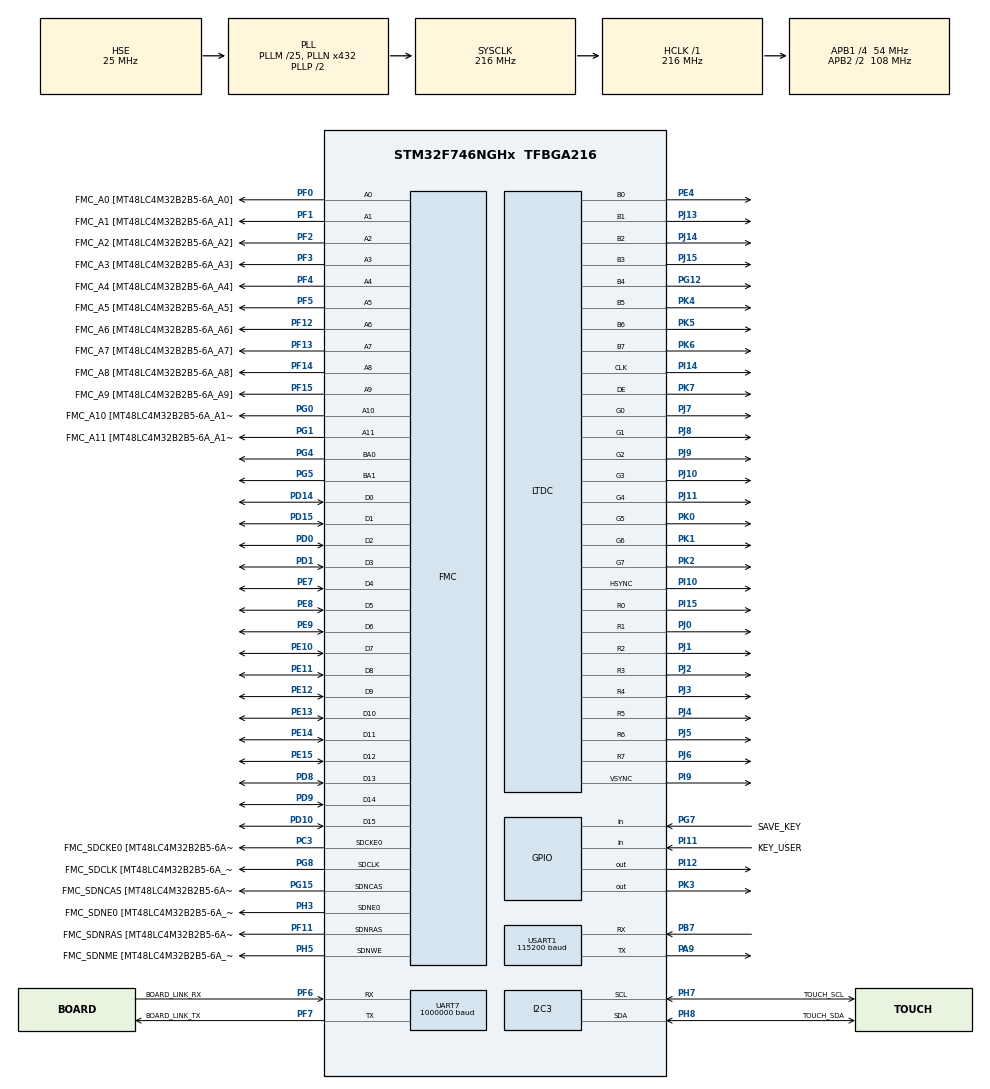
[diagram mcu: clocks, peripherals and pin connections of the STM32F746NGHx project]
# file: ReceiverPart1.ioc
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Dma.Request0=UART7_RX
Dma.UART7_RX.0.Direction=DMA_PERIPH_TO_MEMORY
Dma.UART7_RX.0.FIFOMode=DMA_FIFOMODE_DISABLE
Dma.UART7_RX.0.Instance=DMA1_Stream3
Dma.UART7_RX.0.MemDataAlignment=DMA_MDATAALIGN_BYTE
Dma.UART7_RX.0.MemInc=DMA_MINC_ENABLE
Dma.UART7_RX.0.Mode=DMA_CIRCULAR
Dma.UART7_RX.0.PeriphDataAlignment=DMA_PDATAALIGN_BYTE
Dma.UART7_RX.0.PeriphInc=DMA_PINC_DISABLE
Dma.UART7_RX.0.Priority=DMA_PRIORITY_HIGH
CORTEX_M7.default_mode_Activation=0
FMC.CASLatency1=FMC_SDRAM_CAS_LATENCY_2
FMC.ExitSelfRefreshDelay1=7
FMC.LoadToActiveDelay1=2
FMC.RCDDelay1=2
FMC.RPDelay1=2
FMC.ReadBurst1=FMC_SDRAM_RBURST_ENABLE
FMC.RowCycleDelay1=7
FMC.SDClockPeriod1=FMC_SDRAM_CLOCK_PERIOD_2
FMC.SelfRefreshTime1=4
FMC.WriteRecoveryTime1=2
I2C3.Timing=0x00C0EAFF
LTDC.ActiveH=272
LTDC.ActiveW=480
LTDC.Alpha_L0=255
LTDC.FBStartAdress_L0=0xC0000000
LTDC.HBP=13
LTDC.HFP=32
LTDC.HSync=41
LTDC.ImageHeight_L0=272
LTDC.ImageWidth_L0=480
LTDC.Layers=0
LTDC.PixelFormat_L0=LTDC_PIXEL_FORMAT_RGB565
LTDC.VBP=2
LTDC.VFP=2
LTDC.VSync=10
LTDC.WindowX1_L0=480
LTDC.WindowY1_L0=272
Mcu.Family=STM32F7
Mcu.Name=STM32F746NGHx
Mcu.Package=TFBGA216
NVIC.DMA1_Stream3_IRQn=true\:5\:0\:false\:false\:true\:true\:true\:true
NVIC.PriorityGroup=NVIC_PRIORITYGROUP_4
NVIC.USART1_IRQn=true\:5\:0\:false\:false\:true\:true\:true\:true
PA13.Mode=Serial_Wire
PA13.Signal=SYS_JTMS-SWDIO
PA14.Mode=Serial_Wire
PA14.Signal=SYS_JTCK-SWCLK
PA9.Mode=Asynchronous
PA9.Signal=USART1_TX
PB7.Mode=Asynchronous
PB7.Signal=USART1_RX
PC3.GPIO_Label=FMC_SDCKE0 [MT48LC4M32B2B5-6A_CKE]
PC3.Mode=SdramChipSelect1_1
PC3.Signal=FMC_SDCKE0
PD0.Signal=FMC_D2_DA2
PD1.Signal=FMC_D3_DA3
PD10.Signal=FMC_D15_DA15
PD14.Signal=FMC_D0_DA0
PD15.Signal=FMC_D1_DA1
PD8.Signal=FMC_D13_DA13
PD9.Signal=FMC_D14_DA14
PE0.GPIO_Label=FMC_NBL0 [MT48LC4M32B2B5-6A_DQM0]
PE0.Signal=FMC_NBL0
PE1.GPIO_Label=FMC_NBL1 [MT48LC4M32B2B5-6A_DQM1]
PE1.Signal=FMC_NBL1
PE10.Signal=FMC_D7_DA7
PE11.Signal=FMC_D8_DA8
PE12.Signal=FMC_D9_DA9
PE13.Signal=FMC_D10_DA10
PE14.Signal=FMC_D11_DA11
PE15.Signal=FMC_D12_DA12
PE7.Signal=FMC_D4_DA4
PE8.Signal=FMC_D5_DA5
PE9.Signal=FMC_D6_DA6
PF0.GPIO_Label=FMC_A0 [MT48LC4M32B2B5-6A_A0]
PF0.Signal=FMC_A0
PF1.GPIO_Label=FMC_A1 [MT48LC4M32B2B5-6A_A1]
PF1.Signal=FMC_A1
PF11.GPIO_Label=FMC_SDNRAS [MT48LC4M32B2B5-6A_RAS]
PF11.Signal=FMC_SDNRAS
PF12.GPIO_Label=FMC_A6 [MT48LC4M32B2B5-6A_A6]
PF12.Signal=FMC_A6
PF13.GPIO_Label=FMC_A7 [MT48LC4M32B2B5-6A_A7]
PF13.Signal=FMC_A7
PF14.GPIO_Label=FMC_A8 [MT48LC4M32B2B5-6A_A8]
PF14.Signal=FMC_A8
PF15.GPIO_Label=FMC_A9 [MT48LC4M32B2B5-6A_A9]
PF15.Signal=FMC_A9
PF2.GPIO_Label=FMC_A2 [MT48LC4M32B2B5-6A_A2]
PF2.Signal=FMC_A2
PF3.GPIO_Label=FMC_A3 [MT48LC4M32B2B5-6A_A3]
PF3.Signal=FMC_A3
PF4.GPIO_Label=FMC_A4 [MT48LC4M32B2B5-6A_A4]
PF4.Signal=FMC_A4
PF5.GPIO_Label=FMC_A5 [MT48LC4M32B2B5-6A_A5]
PF5.Signal=FMC_A5
PF6.GPIO_Label=BOARD_LINK_RX
PF6.Mode=Asynchronous
PF6.Signal=UART7_RX
PG0.GPIO_Label=FMC_A10 [MT48LC4M32B2B5-6A_A10]
PG0.Signal=FMC_A10
PG1.GPIO_Label=FMC_A11 [MT48LC4M32B2B5-6A_A11]
PG1.Signal=FMC_A11
PF7.GPIO_Label=BOARD_LINK_TX
PF7.Mode=Asynchronous
PF7.Signal=UART7_TX
PG15.GPIO_Label=FMC_SDNCAS [MT48LC4M32B2B5-6A_CAS]
PG15.Signal=FMC_SDNCAS
PG4.Signal=FMC_A14_BA0
PG5.Signal=FMC_A15_BA1
PG8.GPIO_Label=FMC_SDCLK [MT48LC4M32B2B5-6A_CLK]
PG8.Signal=FMC_SDCLK
PH0/OSC_IN.Mode=HSE-External-Oscillator
PH0/OSC_IN.Signal=RCC_OSC_IN
PH1/OSC_OUT.Mode=HSE-External-Oscillator
PH1/OSC_OUT.Signal=RCC_OSC_OUT
PH3.GPIO_Label=FMC_SDNE0 [MT48LC4M32B2B5-6A_CS]
PH3.Mode=SdramChipSelect1_1
PH3.Signal=FMC_SDNE0
PH5.GPIO_Label=FMC_SDNME [MT48LC4M32B2B5-6A_WE]
PH5.Signal=FMC_SDNWE
PH7.GPIO_Label=TOUCH_SCL
PH7.Mode=I2C
PH7.Signal=I2C3_SCL
PH8.GPIO_Label=TOUCH_SDA
PH8.Mode=I2C
PH8.Signal=I2C3_SDA
PI11.GPIO_Label=KEY_USER
PI11.GPIO_PuPd=GPIO_PULLUP
PI11.Signal=GPIO_Input
PG7.GPIO_Label=SAVE_KEY
PG7.GPIO_PuPd=GPIO_PULLUP
PG7.Signal=GPIO_Input
PI12.PinState=GPIO_PIN_SET
PI12.Signal=GPIO_Output
PK3.Signal=GPIO_Output
PE4.Mode=RGB565
PE4.Signal=LTDC_B0
PJ13.Mode=RGB565
PJ13.Signal=LTDC_B1
PJ14.Mode=RGB565
PJ14.Signal=LTDC_B2
PJ15.Mode=RGB565
PJ15.Signal=LTDC_B3
PG12.Mode=RGB565
PG12.Signal=LTDC_B4
PK4.Mode=RGB565
PK4.Signal=LTDC_B5
PK5.Mode=RGB565
PK5.Signal=LTDC_B6
PK6.Mode=RGB565
PK6.Signal=LTDC_B7
PJ7.Mode=RGB565
PJ7.Signal=LTDC_G0
PJ8.Mode=RGB565
PJ8.Signal=LTDC_G1
PJ9.Mode=RGB565
PJ9.Signal=LTDC_G2
PJ10.Mode=RGB565
PJ10.Signal=LTDC_G3
PJ11.Mode=RGB565
PJ11.Signal=LTDC_G4
PK0.Mode=RGB565
PK0.Signal=LTDC_G5
PK1.Mode=RGB565
PK1.Signal=LTDC_G6
PK2.Mode=RGB565
PK2.Signal=LTDC_G7
PI15.Mode=RGB565
PI15.Signal=LTDC_R0
PJ0.Mode=RGB565
PJ0.Signal=LTDC_R1
PJ1.Mode=RGB565
PJ1.Signal=LTDC_R2
PJ2.Mode=RGB565
PJ2.Signal=LTDC_R3
PJ3.Mode=RGB565
PJ3.Signal=LTDC_R4
PJ4.Mode=RGB565
PJ4.Signal=LTDC_R5
PJ5.Mode=RGB565
PJ5.Signal=LTDC_R6
PJ6.Mode=RGB565
PJ6.Signal=LTDC_R7
PI10.Mode=RGB565
PI10.Signal=LTDC_HSYNC
PI9.Mode=RGB565
PI9.Signal=LTDC_VSYNC
PI14.Mode=RGB565
PI14.Signal=LTDC_CLK
PK7.Mode=RGB565
PK7.Signal=LTDC_DE
ProjectManager.HeapSize=0x200
ProjectManager.StackSize=0x400
ProjectManager.TargetToolchain=STM32CubeIDE
RCC.AHBFreq_Value=216000000
RCC.APB1CLKDivider=RCC_HCLK_DIV4
RCC.APB1Freq_Value=54000000
RCC.APB1TimFreq_Value=108000000
RCC.APB2CLKDivider=RCC_HCLK_DIV2
RCC.APB2Freq_Value=108000000
RCC.APB2TimFreq_Value=216000000
RCC.CortexFreq_Value=216000000
RCC.HCLKFreq_Value=216000000
RCC.HSE_VALUE=25000000
RCC.HSI_VALUE=16000000
RCC.LSE_VALUE=32768
RCC.PLLM=25
RCC.PLLN=432
RCC.PLLSAIN=192
RCC.PLLSAIR=5
RCC.PLLSAIRDiv=RCC_PLLSAIDIVR_4
RCC.PLLSourceVirtual=RCC_PLLSOURCE_HSE
RCC.SYSCLKFreq_VALUE=216000000
RCC.SYSCLKSource=RCC_SYSCLKSOURCE_PLLCLK
RCC.USBFreq_Value=216000000
RCC.VCOOutputFreq_Value=432000000
SH.FMC_A0.0=FMC_A0,12b-sda1
SH.FMC_A1.0=FMC_A1,12b-sda1
SH.FMC_A10.0=FMC_A10,12b-sda1
SH.FMC_A11.0=FMC_A11,12b-sda1
SH.FMC_A14_BA0.0=FMC_BA0,FourSdramBanks1
SH.FMC_A15_BA1.0=FMC_BA1,FourSdramBanks1
SH.FMC_A2.0=FMC_A2,12b-sda1
SH.FMC_A3.0=FMC_A3,12b-sda1
SH.FMC_A4.0=FMC_A4,12b-sda1
SH.FMC_A5.0=FMC_A5,12b-sda1
SH.FMC_A6.0=FMC_A6,12b-sda1
SH.FMC_A7.0=FMC_A7,12b-sda1
SH.FMC_A8.0=FMC_A8,12b-sda1
SH.FMC_A9.0=FMC_A9,12b-sda1
SH.FMC_D0_DA0.0=FMC_D0,sd-16b-d1
SH.FMC_D10_DA10.0=FMC_D10,sd-16b-d1
SH.FMC_D11_DA11.0=FMC_D11,sd-16b-d1
SH.FMC_D12_DA12.0=FMC_D12,sd-16b-d1
SH.FMC_D13_DA13.0=FMC_D13,sd-16b-d1
SH.FMC_D14_DA14.0=FMC_D14,sd-16b-d1
SH.FMC_D15_DA15.0=FMC_D15,sd-16b-d1
SH.FMC_D1_DA1.0=FMC_D1,sd-16b-d1
SH.FMC_D2_DA2.0=FMC_D2,sd-16b-d1
SH.FMC_D3_DA3.0=FMC_D3,sd-16b-d1
SH.FMC_D4_DA4.0=FMC_D4,sd-16b-d1
SH.FMC_D5_DA5.0=FMC_D5,sd-16b-d1
SH.FMC_D6_DA6.0=FMC_D6,sd-16b-d1
SH.FMC_D7_DA7.0=FMC_D7,sd-16b-d1
SH.FMC_D8_DA8.0=FMC_D8,sd-16b-d1
SH.FMC_D9_DA9.0=FMC_D9,sd-16b-d1
SH.FMC_NBL0.0=FMC_NBL0
SH.FMC_NBL1.0=FMC_NBL1
SH.FMC_SDCLK.0=FMC_SDCLK,12b-sda1
SH.FMC_SDNCAS.0=FMC_SDNCAS,12b-sda1
SH.FMC_SDNRAS.0=FMC_SDNRAS,12b-sda1
SH.FMC_SDNWE.0=FMC_SDNWE,12b-sda1
USART1.BaudRate=115200
USART1.VirtualMode-Asynchronous=VM_ASYNC
UART7.BaudRate=1000000
UART7.VirtualMode-Asynchronous=VM_ASYNC
board=STM32F746G-DISCO

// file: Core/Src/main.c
/* USER CODE BEGIN Header */
/**
  ******************************************************************************
  * @file           : main.c
  * @brief          : Main program body
  ******************************************************************************
  * @attention
  *
  * Copyright (c) 2026 STMicroelectronics.
  * All rights reserved.
  *
  * This software is licensed under terms that can be found in the LICENSE file
  * in the root directory of this software component.
  * If no LICENSE file comes with this software, it is provided AS-IS.
  *
  ******************************************************************************
  */
/* USER CODE END Header */
#include "main.h"
#include "ltdc.h"
#include "usart.h"
#include "gpio.h"
#include "fmc.h"
#include "i2c.h"

/* USER CODE BEGIN Includes */
#include "app_acquisition.h"
#include "app_role.h"
#include "app_receiver.h"
/* USER CODE END Includes */

void SystemClock_Config(void);

int main(void)
{

  /* MCU Configuration--------------------------------------------------------*/

  /* Reset of all peripherals, Initializes the Flash interface and the Systick. */
  HAL_Init();

  /* Configure the system clock */
  SystemClock_Config();

  /* Initialize all configured peripherals */
  MX_GPIO_Init();
  MX_USART1_UART_Init();   /* ST-LINK VCP，供电脑调试 */
  MX_UART7_UART_Init();    /* PF7/PF6，两块开发板之间的 1 Mbps 链路 */

#if APP_ROLE == APP_ROLE_RECEIVER
  MX_FMC_Init();
  MX_LTDC_Init();
  MX_I2C3_Init();
#endif
  /* USER CODE BEGIN 2 */
  /*
   * 以上代码由 CubeMX 生成。
   * 这里进入我们自己的应用层：初始化 SDRAM、帧缓冲区、UART 接收和界面。
   */
#if APP_ROLE == APP_ROLE_RECEIVER
  App_ReceiverInit();
#else
  App_AcquisitionInit();
#endif
  /* USER CODE END 2 */

  /* Infinite loop */
  while (1)
  {

    /* USER CODE BEGIN 3 */
#if APP_ROLE == APP_ROLE_RECEIVER
    /* 解析板间串口/PC 调试串口，扫描触摸按键并刷新波形。 */
    App_ReceiverLoop();
#else
    /* 采集演示固件：通过 UART7 发送双通道测试帧并接收换档命令。 */
    App_AcquisitionLoop();
#endif
  }
  /* USER CODE END 3 */
}

void SystemClock_Config(void)
{
  RCC_OscInitTypeDef RCC_OscInitStruct = {0};
  RCC_ClkInitTypeDef RCC_ClkInitStruct = {0};

  /** Configure the main internal regulator output voltage
  */
  __HAL_RCC_PWR_CLK_ENABLE();
  __HAL_PWR_VOLTAGESCALING_CONFIG(PWR_REGULATOR_VOLTAGE_SCALE1);

  /** Initializes the RCC Oscillators according to the specified parameters
  * in the RCC_OscInitTypeDef structure.
  */
  RCC_OscInitStruct.OscillatorType = RCC_OSCILLATORTYPE_HSE;
  RCC_OscInitStruct.HSEState = RCC_HSE_ON;
  RCC_OscInitStruct.PLL.PLLState = RCC_PLL_ON;
  RCC_OscInitStruct.PLL.PLLSource = RCC_PLLSOURCE_HSE;
  RCC_OscInitStruct.PLL.PLLM = 25;
  RCC_OscInitStruct.PLL.PLLN = 432;
  RCC_OscInitStruct.PLL.PLLP = RCC_PLLP_DIV2;
  RCC_OscInitStruct.PLL.PLLQ = 2;
  if (HAL_RCC_OscConfig(&RCC_OscInitStruct) != HAL_OK)
  {
    Error_Handler();
  }

  /** Activate the Over-Drive mode
  */
  if (HAL_PWREx_EnableOverDrive() != HAL_OK)
  {
    Error_Handler();
  }

  /** Initializes the CPU, AHB and APB buses clocks
  */
  RCC_ClkInitStruct.ClockType = RCC_CLOCKTYPE_HCLK|RCC_CLOCKTYPE_SYSCLK
                              |RCC_CLOCKTYPE_PCLK1|RCC_CLOCKTYPE_PCLK2;
  RCC_ClkInitStruct.SYSCLKSource = RCC_SYSCLKSOURCE_PLLCLK;
  RCC_ClkInitStruct.AHBCLKDivider = RCC_SYSCLK_DIV1;
  RCC_ClkInitStruct.APB1CLKDivider = RCC_HCLK_DIV4;
  RCC_ClkInitStruct.APB2CLKDivider = RCC_HCLK_DIV2;

  if (HAL_RCC_ClockConfig(&RCC_ClkInitStruct, FLASH_LATENCY_7) != HAL_OK)
  {
    Error_Handler();
  }
}

void Error_Handler(void)
{
  __disable_irq();
  while (1)
  {
  }
}
